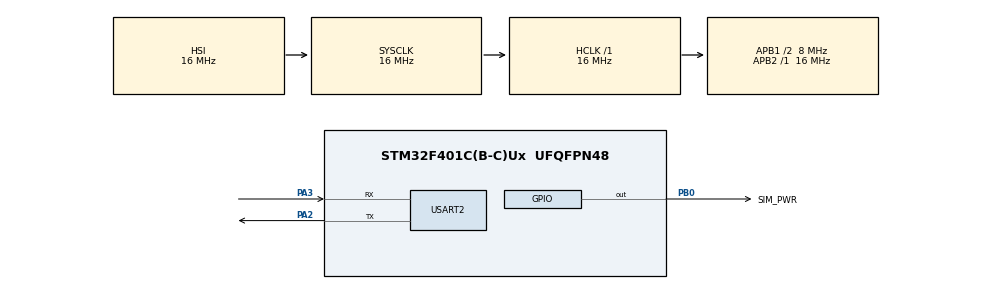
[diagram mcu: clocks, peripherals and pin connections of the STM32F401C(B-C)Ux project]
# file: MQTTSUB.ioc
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Mcu.Family=STM32F4
Mcu.Name=STM32F401C(B-C)Ux
Mcu.Package=UFQFPN48
NVIC.PriorityGroup=NVIC_PRIORITYGROUP_4
NVIC.USART2_IRQn=true\:0\:0\:false\:false\:true\:true\:true
PA13.Mode=Serial_Wire
PA13.Signal=SYS_JTMS-SWDIO
PA14.Mode=Serial_Wire
PA14.Signal=SYS_JTCK-SWCLK
PA2.Mode=Asynchronous
PA2.Signal=USART2_TX
PA3.Mode=Asynchronous
PA3.Signal=USART2_RX
PB0.GPIO_Label=SIM_PWR
PB0.Signal=GPIO_Output
ProjectManager.HeapSize=0x200
ProjectManager.StackSize=0x400
ProjectManager.TargetToolchain=STM32CubeIDE
RCC.48MHZClocksFreq_Value=26880000
RCC.AHBFreq_Value=16000000
RCC.APB1CLKDivider=RCC_HCLK_DIV2
RCC.APB1Freq_Value=8000000
RCC.APB1TimFreq_Value=16000000
RCC.APB2Freq_Value=16000000
RCC.APB2TimFreq_Value=16000000
RCC.CortexFreq_Value=16000000
RCC.HCLKFreq_Value=16000000
RCC.HSE_VALUE=25000000
RCC.HSI_VALUE=16000000
RCC.LSE_VALUE=32768
RCC.PLLM=25
RCC.PLLN=168
RCC.SYSCLKFreq_VALUE=16000000
RCC.VCOOutputFreq_Value=107520000
USART2.VirtualMode=VM_ASYNC
board=custom

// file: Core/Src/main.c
/* USER CODE BEGIN Header */
/**
  ******************************************************************************
  * @file           : main.c
  * @brief          : Main program body
  ******************************************************************************
  * @attention
  *
  * <h2><center>&copy; Copyright (c) 2020 STMicroelectronics.
  * All rights reserved.</center></h2>
  *
  * This software component is licensed by ST under BSD 3-Clause license,
  * the "License"; You may not use this file except in compliance with the
  * License. You may obtain a copy of the License at:
  *                        opensource.org/licenses/BSD-3-Clause
  *
  ******************************************************************************
  */
/* USER CODE END Header */
#include "main.h"
#include "usart.h"
#include "gpio.h"

/* USER CODE BEGIN Includes */
#include <stdlib.h>
#include "MQTTSim800.h"
/* USER CODE END Includes */

/* USER CODE BEGIN PV */
SIM800_t SIM800;
/* USER CODE END PV */

void SystemClock_Config(void);

/* USER CODE BEGIN 0 */
void HAL_UART_RxCpltCallback(UART_HandleTypeDef *huart) {
    if (huart == UART_SIM800) {
        Sim800_RxCallBack();
    }
}

/* USER CODE END 0 */

int main(void)
{

  /* MCU Configuration--------------------------------------------------------*/

  /* Reset of all peripherals, Initializes the Flash interface and the Systick. */
  HAL_Init();

  /* Configure the system clock */
  SystemClock_Config();

  /* Initialize all configured peripherals */
  MX_GPIO_Init();
  MX_USART2_UART_Init();
  /* USER CODE BEGIN 2 */

    // On SIM800 power if use
    HAL_GPIO_WritePin(SIM_PWR_GPIO_Port, SIM_PWR_Pin, GPIO_PIN_RESET);
    HAL_Delay(3000);
    HAL_GPIO_WritePin(SIM_PWR_GPIO_Port, SIM_PWR_Pin, GPIO_PIN_SET);
    HAL_Delay(10000);

    // MQQT settings
    SIM800.sim.apn = "internet";
    SIM800.sim.apn_user = "";
    SIM800.sim.apn_pass = "";
    SIM800.mqttServer.host = "mqtt.mqtt.ru";
    SIM800.mqttServer.port = 1883;
    SIM800.mqttClient.username = "user";
    SIM800.mqttClient.pass = "pass";
    SIM800.mqttClient.clientID = "TestSub";
    SIM800.mqttClient.keepAliveInterval = 120;

    MQTT_Init();

    uint8_t sub = 0;

    //Test data
    uint8_t pub_uint8 = 1;
    uint16_t pub_uint16 = 2;
    uint32_t pub_uint32 = 3;
    float pub_float = 1.1;
    double pub_double = 2.2;

    // Check MQTT broker topic
    SIM800.mqttCheckTopic = "MQTTCheck";

  /* USER CODE END 2 */

  /* Infinite loop */
  /* USER CODE BEGIN WHILE */
    while (1) {
        if (SIM800.mqttServer.connect == 0) {
            MQTT_Init();
            sub = 0;
        }
        if (SIM800.mqttServer.connect == 1) {
            if(sub == 0){
                MQTT_Sub("test");
                sub = 1;
            }

            MQTT_Pub("STM32/string", "string");
            MQTT_PubUint8("STM32/uint8", pub_uint8);
            MQTT_PubUint16("STM32/uint16", pub_uint16);
            MQTT_PubUint32("STM32/uint32", pub_uint32);
            MQTT_PubFloat("STM32/float", pub_float);
            MQTT_PubDouble("STM32/double", pub_double);

            if(SIM800.mqttReceive.newEvent) {
                unsigned char *topic = SIM800.mqttReceive.topic;
                int payload = atoi(SIM800.mqttReceive.payload);
                SIM800.mqttReceive.newEvent = 0;
            }

            //Check MQTT
				    MQTT_Check();
        }
        HAL_Delay(1000);
    /* USER CODE END WHILE */

    }
}

void SystemClock_Config(void)
{
  RCC_OscInitTypeDef RCC_OscInitStruct = {0};
  RCC_ClkInitTypeDef RCC_ClkInitStruct = {0};

  /** Configure the main internal regulator output voltage
  */
  __HAL_RCC_PWR_CLK_ENABLE();
  __HAL_PWR_VOLTAGESCALING_CONFIG(PWR_REGULATOR_VOLTAGE_SCALE2);
  /** Initializes the RCC Oscillators according to the specified parameters
  * in the RCC_OscInitTypeDef structure.
  */
  RCC_OscInitStruct.OscillatorType = RCC_OSCILLATORTYPE_HSI;
  RCC_OscInitStruct.HSIState = RCC_HSI_ON;
  RCC_OscInitStruct.HSICalibrationValue = RCC_HSICALIBRATION_DEFAULT;
  RCC_OscInitStruct.PLL.PLLState = RCC_PLL_NONE;
  if (HAL_RCC_OscConfig(&RCC_OscInitStruct) != HAL_OK)
  {
    Error_Handler();
  }
  /** Initializes the CPU, AHB and APB buses clocks
  */
  RCC_ClkInitStruct.ClockType = RCC_CLOCKTYPE_HCLK|RCC_CLOCKTYPE_SYSCLK
                              |RCC_CLOCKTYPE_PCLK1|RCC_CLOCKTYPE_PCLK2;
  RCC_ClkInitStruct.SYSCLKSource = RCC_SYSCLKSOURCE_HSI;
  RCC_ClkInitStruct.AHBCLKDivider = RCC_SYSCLK_DIV1;
  RCC_ClkInitStruct.APB1CLKDivider = RCC_HCLK_DIV2;
  RCC_ClkInitStruct.APB2CLKDivider = RCC_HCLK_DIV1;

  if (HAL_RCC_ClockConfig(&RCC_ClkInitStruct, FLASH_LATENCY_0) != HAL_OK)
  {
    Error_Handler();
  }
}

void Error_Handler(void)
{
    __disable_irq();
    while (1) {
    }
}

/************************ (C) COPYRIGHT STMicroelectronics *****END OF FILE****/
